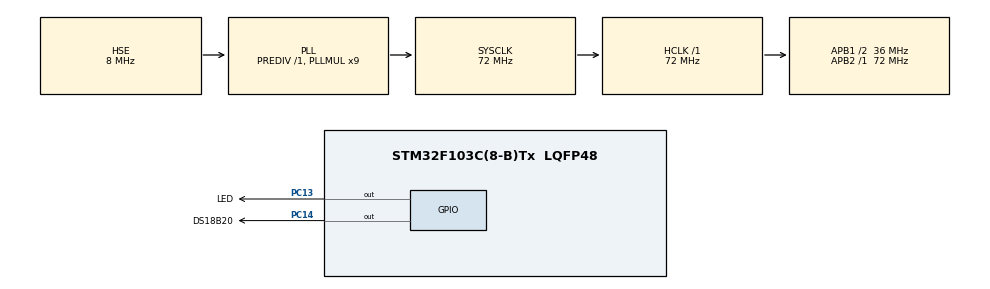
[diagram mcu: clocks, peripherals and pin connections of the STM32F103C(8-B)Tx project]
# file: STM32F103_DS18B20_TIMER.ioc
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Mcu.Family=STM32F1
Mcu.Name=STM32F103C(8-B)Tx
Mcu.Package=LQFP48
NVIC.PriorityGroup=NVIC_PRIORITYGROUP_1
NVIC.RCC_IRQn=true\:0\:0\:false\:true\:true\:1\:true\:false
NVIC.TIM1_UP_IRQn=true\:0\:0\:false\:false\:true\:true\:true
PA13.Mode=Serial_Wire
PA13.Signal=SYS_JTMS-SWDIO
PA14.Mode=Serial_Wire
PA14.Signal=SYS_JTCK-SWCLK
PC13-TAMPER-RTC.GPIO_Label=LED
PC13-TAMPER-RTC.GPIO_Speed=GPIO_SPEED_FREQ_HIGH
PC13-TAMPER-RTC.Signal=GPIO_Output
PC14-OSC32_IN.GPIO_Label=DS18B20
PC14-OSC32_IN.Signal=GPIO_Output
PD0-OSC_IN.Mode=HSE-External-Oscillator
PD0-OSC_IN.Signal=RCC_OSC_IN
PD1-OSC_OUT.Mode=HSE-External-Oscillator
PD1-OSC_OUT.Signal=RCC_OSC_OUT
ProjectManager.HeapSize=0x200
ProjectManager.StackSize=0x400
ProjectManager.TargetToolchain=TrueSTUDIO
RCC.AHBFreq_Value=72000000
RCC.APB1CLKDivider=RCC_HCLK_DIV2
RCC.APB1Freq_Value=36000000
RCC.APB1TimFreq_Value=72000000
RCC.APB2Freq_Value=72000000
RCC.APB2TimFreq_Value=72000000
RCC.HCLKFreq_Value=72000000
RCC.PLLMUL=RCC_PLL_MUL9
RCC.PLLSourceVirtual=RCC_PLLSOURCE_HSE
RCC.SYSCLKFreq_VALUE=72000000
RCC.SYSCLKSource=RCC_SYSCLKSOURCE_PLLCLK
RCC.USBFreq_Value=72000000
TIM1.AutoReloadPreload=TIM_AUTORELOAD_PRELOAD_DISABLE
TIM1.Period=65000
TIM1.Prescaler=72-1
VP_TIM1_VS_ClockSourceINT.Mode=Internal
board=custom

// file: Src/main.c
/* USER CODE BEGIN Header */
/**
  ******************************************************************************
  * @file           : main.c
  * @brief          : Main program body
  ******************************************************************************
  * @attention
  *
  * <h2><center>&copy; Copyright (c) 2019 STMicroelectronics.
  * All rights reserved.</center></h2>
  *
  * This software component is licensed by ST under BSD 3-Clause license,
  * the "License"; You may not use this file except in compliance with the
  * License. You may obtain a copy of the License at:
  *                        opensource.org/licenses/BSD-3-Clause
  *
  ******************************************************************************
  */
/* USER CODE END Header */

#include "main.h"
#include "tim.h"
#include "gpio.h"

/* USER CODE BEGIN Includes */
#include "onewire.h"
#include "ds18b20.h"
#include "string.h"
#include "Zmienne.h"
/* USER CODE END Includes */

/* USER CODE BEGIN PV */
float temperature;
char message[64];
/* USER CODE END PV */

void SystemClock_Config(void);
static void MX_NVIC_Init(void);

int main(void)
{

  /* MCU Configuration--------------------------------------------------------*/

  /* Reset of all peripherals, Initializes the Flash interface and the Systick. */
  HAL_Init();

  /* Configure the system clock */
  SystemClock_Config();

  /* Initialize all configured peripherals */
  MX_GPIO_Init();
  MX_TIM1_Init();

  /* Initialize interrupts */
  MX_NVIC_Init();
  /* USER CODE BEGIN 2 */
 // __HAL_TIM_CLEAR_FLAG(&htim1,TIM_FLAG_UPDATE);
    HAL_TIM_Base_Start_IT(&htim1);
    DS18B20_Init(DS18B20_Resolution_12bits);
  /* USER CODE END 2 */

  /* Infinite loop */
  while (1)
  {

    /* USER CODE BEGIN 3 */
	  DS18B20_ReadAll();
	       DS18B20_StartAll();
	 		uint8_t ROM_tmp[8];
	 		uint8_t i;
	 	for(i = 0; i < DS18B20_Quantity(); i++)
	 		{
	 			if(DS18B20_GetTemperature(i, &temperature))
	 			{
	 				DS18B20_GetROM(i, ROM_tmp);
	 			}
	 		}
	 		HAL_Delay(1000);
  }
  /* USER CODE END 3 */
}

void SystemClock_Config(void)
{
  RCC_OscInitTypeDef RCC_OscInitStruct = {0};
  RCC_ClkInitTypeDef RCC_ClkInitStruct = {0};

  /** Initializes the CPU, AHB and APB busses clocks
  */
  RCC_OscInitStruct.OscillatorType = RCC_OSCILLATORTYPE_HSE;
  RCC_OscInitStruct.HSEState = RCC_HSE_ON;
  RCC_OscInitStruct.HSEPredivValue = RCC_HSE_PREDIV_DIV1;
  RCC_OscInitStruct.HSIState = RCC_HSI_ON;
  RCC_OscInitStruct.PLL.PLLState = RCC_PLL_ON;
  RCC_OscInitStruct.PLL.PLLSource = RCC_PLLSOURCE_HSE;
  RCC_OscInitStruct.PLL.PLLMUL = RCC_PLL_MUL9;
  if (HAL_RCC_OscConfig(&RCC_OscInitStruct) != HAL_OK)
  {
    Error_Handler();
  }
  /** Initializes the CPU, AHB and APB busses clocks
  */
  RCC_ClkInitStruct.ClockType = RCC_CLOCKTYPE_HCLK|RCC_CLOCKTYPE_SYSCLK
                              |RCC_CLOCKTYPE_PCLK1|RCC_CLOCKTYPE_PCLK2;
  RCC_ClkInitStruct.SYSCLKSource = RCC_SYSCLKSOURCE_PLLCLK;
  RCC_ClkInitStruct.AHBCLKDivider = RCC_SYSCLK_DIV1;
  RCC_ClkInitStruct.APB1CLKDivider = RCC_HCLK_DIV2;
  RCC_ClkInitStruct.APB2CLKDivider = RCC_HCLK_DIV1;

  if (HAL_RCC_ClockConfig(&RCC_ClkInitStruct, FLASH_LATENCY_2) != HAL_OK)
  {
    Error_Handler();
  }
}

/**
  * @brief NVIC Configuration.
  * @retval None
  */
static void MX_NVIC_Init(void)
{
  /* RCC_IRQn interrupt configuration */
  HAL_NVIC_SetPriority(RCC_IRQn, 0, 0);
  HAL_NVIC_EnableIRQ(RCC_IRQn);
}

/* USER CODE BEGIN 4 */
void HAL_TIM_PeriodElapsedCallback(TIM_HandleTypeDef *htim){
	if(htim->Instance == TIM1){ // Je¿eli przerwanie pochodzi od timera 10
					czas++;
		}
}
/* USER CODE END 4 */

void Error_Handler(void)
{
}

/************************ (C) COPYRIGHT STMicroelectronics *****END OF FILE****/
